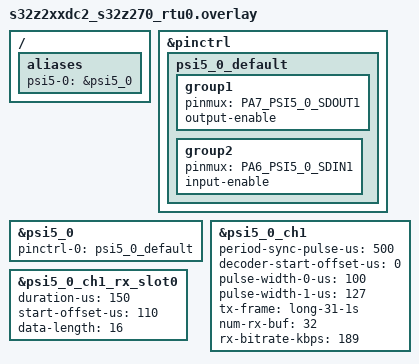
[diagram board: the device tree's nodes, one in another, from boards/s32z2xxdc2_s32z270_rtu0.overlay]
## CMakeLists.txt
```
# SPDX-License-Identifier: Apache-2.0

cmake_minimum_required(VERSION 3.28.0)

find_package(Zephyr REQUIRED HINTS $ENV{ZEPHYR_BASE})
project(psi5)

target_sources(app PRIVATE src/main.c)
```

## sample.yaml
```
sample:
  name: PSI5 driver sample

tests:
  sample.drivers.psi5:
    tags:
      - drivers
      - psi5
    depends_on: psi5
    filter: dt_alias_exists("psi5-0")
    harness: sensor
```

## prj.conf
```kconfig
CONFIG_PSI5=y
CONFIG_PSI5_LOG_LEVEL_DBG=y
CONFIG_LOG=y
```

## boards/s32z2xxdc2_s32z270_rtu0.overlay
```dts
/*
 * Copyright 2025 NXP
 *
 * SPDX-License-Identifier: Apache-2.0
 */

/ {
	aliases {
		psi5-0 = &psi5_0;
	};
};

&pinctrl {
	psi5_0_default: psi5_0_default {
		group1 {
			pinmux = <PA7_PSI5_0_SDOUT1>;
			output-enable;
		};

		group2 {
			pinmux = <PA6_PSI5_0_SDIN1>;
			input-enable;
		};
	};
};

&psi5_0 {
	pinctrl-0 = <&psi5_0_default>;
	pinctrl-names = "default";
	status = "okay";
};

&psi5_0_ch1 {
	period-sync-pulse-us = <500>;
	decoder-start-offset-us = <0>;
	pulse-width-0-us = <100>;
	pulse-width-1-us = <127>;
	tx-frame = "long-31-1s";
	num-rx-buf = <32>;
	rx-bitrate-kbps = <189>;
	status = "okay";
};

&psi5_0_ch1_rx_slot0 {
	duration-us = <150>;
	start-offset-us = <110>;
	data-length = <16>;
	status = "okay";
};
```

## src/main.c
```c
/*
 * Copyright 2025 NXP
 *
 * SPDX-License-Identifier: Apache-2.0
 */

#include <zephyr/logging/log.h>
LOG_MODULE_REGISTER(psi5_sample, LOG_LEVEL_DBG);

#include <zephyr/kernel.h>

#include <zephyr/drivers/psi5/psi5.h>

#define PSI5_NODE          DT_ALIAS(psi5_0)
#define PSI5_CHANNEL       1
#define PSI5_MAX_RX_BUFFER 1

struct psi5_frame serial_frame[PSI5_MAX_RX_BUFFER];

struct psi5_frame data_frame[PSI5_MAX_RX_BUFFER];

void tx_cb(const struct device *dev, uint8_t channel_id, int status, void *user_data)
{
	LOG_INF("Transmitted data on channel %d", channel_id);
}

void rx_serial_frame_cb(const struct device *dev, uint8_t channel_id, uint32_t num_frame,
			void *user_data)
{

	if (num_frame == PSI5_MAX_RX_BUFFER) {
		LOG_INF("Received a frame on channel %d, "
			"id: %d, data: 0x%X, timestamp: 0x%X, slot: %d",
			channel_id, serial_frame->serial.id, serial_frame->serial.data,
			serial_frame->timestamp, serial_frame->slot_number);
	} else {
		LOG_INF("Error received on channel %d", channel_id);
	}
}

void rx_data_frame_cb(const struct device *dev, uint8_t channel_id, uint32_t num_frame,
		      void *user_data)
{

	if (num_frame == PSI5_MAX_RX_BUFFER) {
		LOG_INF("Received a frame on channel %d, "
			"data: 0x%X, timestamp: 0x%X",
			channel_id, data_frame->data, data_frame->timestamp);
	} else {
		LOG_INF("Error received on channel %d", channel_id);
	}
}

struct psi5_rx_callback_config serial_cb_cfg = {
	.callback = rx_serial_frame_cb,
	.frame = &serial_frame[0],
	.max_num_frame = PSI5_MAX_RX_BUFFER,
	.user_data = NULL,
};

struct psi5_rx_callback_config data_cb_cfg = {
	.callback = rx_data_frame_cb,
	.frame = &data_frame[0],
	.max_num_frame = PSI5_MAX_RX_BUFFER,
	.user_data = NULL,
};

struct psi5_rx_callback_configs callback_configs = {
	.serial_frame = &serial_cb_cfg,
	.data_frame = &data_cb_cfg,
};

int main(void)
{
	const struct device *const dev = DEVICE_DT_GET(PSI5_NODE);
	uint64_t send_data = 0x1234;

	psi5_register_callback(dev, PSI5_CHANNEL, callback_configs);

	psi5_start_sync(dev, PSI5_CHANNEL);

	psi5_send(dev, PSI5_CHANNEL, send_data, K_MSEC(100), tx_cb, NULL);

	while (true) {
		/* To transmit and receive data */
	}

	return 0;
}
```
